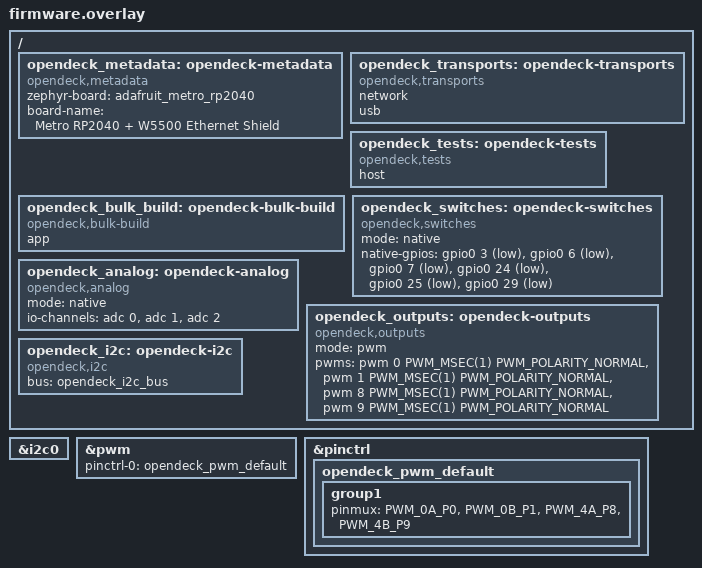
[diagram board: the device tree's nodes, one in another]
#include <zephyr/dt-bindings/pwm/pwm.h>
#include <zephyr/dt-bindings/pinctrl/rpi-pico-rp2040-pinctrl.h>

/ {
    opendeck_metadata: opendeck-metadata {
        compatible = "opendeck,metadata";
        zephyr-board = "adafruit_metro_rp2040";
        board-name = "Metro RP2040 + W5500 Ethernet Shield";
    };

    opendeck_transports: opendeck-transports {
        compatible = "opendeck,transports";
        network;
        usb;
    };

    opendeck_tests: opendeck-tests {
        compatible = "opendeck,tests";
        host;
    };

    opendeck_bulk_build: opendeck-bulk-build {
        compatible = "opendeck,bulk-build";
        app;
    };

    opendeck_switches: opendeck-switches {
        compatible = "opendeck,switches";
        mode = "native";
        native-gpios =
            <&gpio0 3 (GPIO_PULL_UP | GPIO_ACTIVE_LOW)>,
            <&gpio0 6 (GPIO_PULL_UP | GPIO_ACTIVE_LOW)>,
            <&gpio0 7 (GPIO_PULL_UP | GPIO_ACTIVE_LOW)>,
            <&gpio0 24 (GPIO_PULL_UP | GPIO_ACTIVE_LOW)>,
            <&gpio0 25 (GPIO_PULL_UP | GPIO_ACTIVE_LOW)>,
            <&gpio0 29 (GPIO_PULL_UP | GPIO_ACTIVE_LOW)>;
    };

    opendeck_analog: opendeck-analog {
        compatible = "opendeck,analog";
        mode = "native";
        io-channels =
            <&adc 0>,
            <&adc 1>,
            <&adc 2>;
    };

    opendeck_outputs: opendeck-outputs {
        compatible = "opendeck,outputs";
        mode = "pwm";
        pwms =
            <&pwm 0 PWM_MSEC(1) PWM_POLARITY_NORMAL>,
            <&pwm 1 PWM_MSEC(1) PWM_POLARITY_NORMAL>,
            <&pwm 8 PWM_MSEC(1) PWM_POLARITY_NORMAL>,
            <&pwm 9 PWM_MSEC(1) PWM_POLARITY_NORMAL>;
    };

    opendeck_i2c: opendeck-i2c {
        compatible = "opendeck,i2c";
        bus = <&opendeck_i2c_bus>;
    };
};

&i2c0 {
    status = "okay";
};

&pwm {
    pinctrl-0 = <&opendeck_pwm_default>;
    pinctrl-names = "default";
    status = "okay";
};

&pinctrl {
    opendeck_pwm_default: opendeck_pwm_default {
        group1 {
            pinmux = <PWM_0A_P0>,
                     <PWM_0B_P1>,
                     <PWM_4A_P8>,
                     <PWM_4B_P9>;
        };
    };
};
